# PIC32MZ2048EFM144 register map
Registers are 32-bit, access not given, reset 0x0 unless marked. A register's access mark holds for its fields unless they carry their own. Offsets are from the block's base; [hi:lo] are bit positions; {n}, {i} and the like mark numbered series; 'fields as' and 'values as' point back to an identical list.

## PMP — PMP peripheral
Base 0xBF82E000
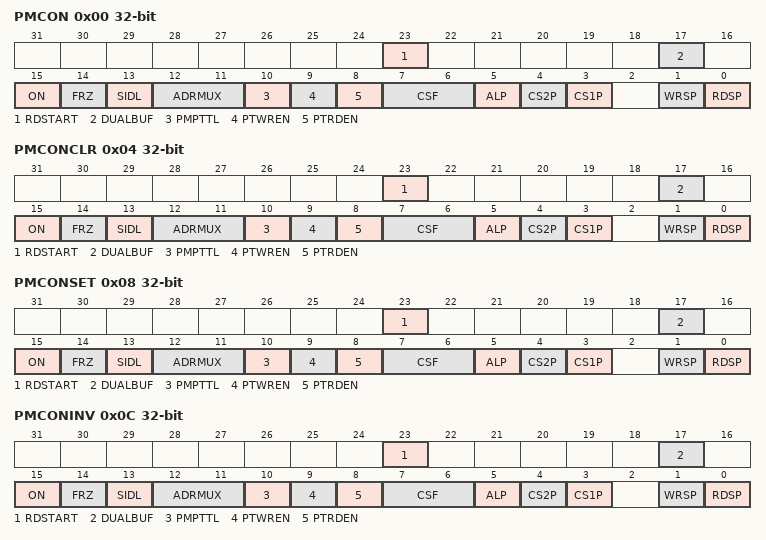
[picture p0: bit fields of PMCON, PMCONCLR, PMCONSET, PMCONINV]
0x00 PMCON
  [23] RDSTART, [17] DUALBUF, [15] ON, [14] FRZ, [13] SIDL, [12:11] ADRMUX, [10] PMPTTL, [9] PTWREN, [8] PTRDEN, [7:6] CSF, [5] ALP, [4] CS2P, [3] CS1P, [1] WRSP, [0] RDSP
0x04 PMCONCLR
  fields as PMCON
0x08 PMCONSET
  fields as PMCON
0x0C PMCONINV
  fields as PMCON
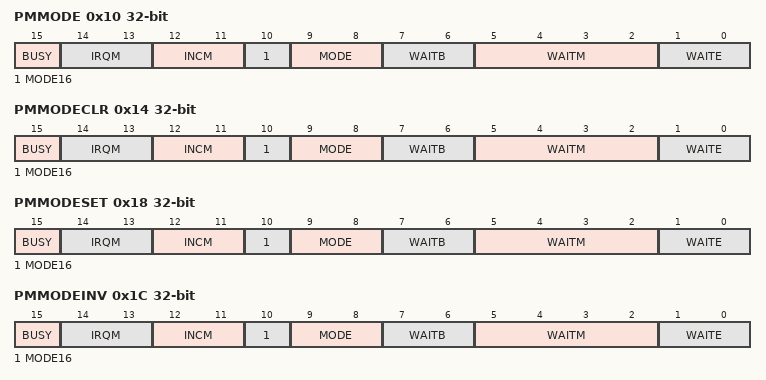
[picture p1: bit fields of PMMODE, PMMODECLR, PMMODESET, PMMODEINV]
0x10 PMMODE
  [15] BUSY, [14:13] IRQM, [12:11] INCM, [10] MODE16, [9:8] MODE, [7:6] WAITB, [5:2] WAITM, [1:0] WAITE
0x14 PMMODECLR
  fields as PMMODE
0x18 PMMODESET
  fields as PMMODE
0x1C PMMODEINV
  fields as PMMODE
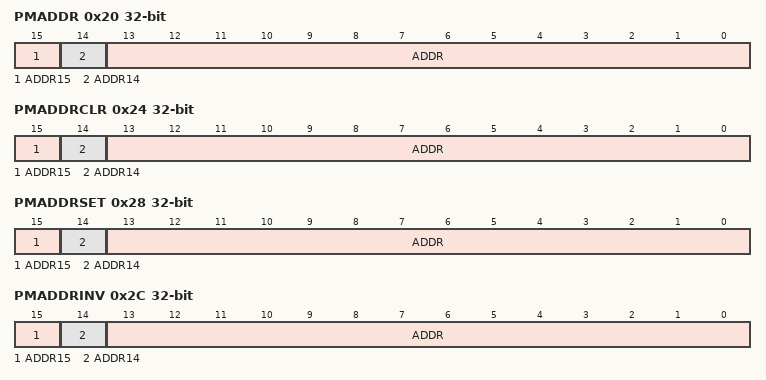
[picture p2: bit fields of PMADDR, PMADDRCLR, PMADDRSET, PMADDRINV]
0x20 PMADDR
  [15] ADDR15, [14] ADDR14, [13:0] ADDR
0x24 PMADDRCLR
  [15] ADDR15, [14] ADDR14, [13:0] ADDR
0x28 PMADDRSET
  [15] ADDR15, [14] ADDR14, [13:0] ADDR
0x2C PMADDRINV
  [15] ADDR15, [14] ADDR14, [13:0] ADDR
0x30 PMDOUT
  [31:0] DATAOUT
0x34 PMDOUTCLR
  [31:0] DATAOUT
0x38 PMDOUTSET
  [31:0] DATAOUT
0x3C PMDOUTINV
  [31:0] DATAOUT
0x40 PMDIN
  [31:0] DATAIN
0x44 PMDINCLR
  [31:0] DATAIN
0x48 PMDINSET
  [31:0] DATAIN
0x4C PMDININV
  [31:0] DATAIN
0x50 PMAEN
  [23:0] PTEN
0x54 PMAENCLR
  [23:0] PTEN
0x58 PMAENSET
  [23:0] PTEN
0x5C PMAENINV
  [23:0] PTEN
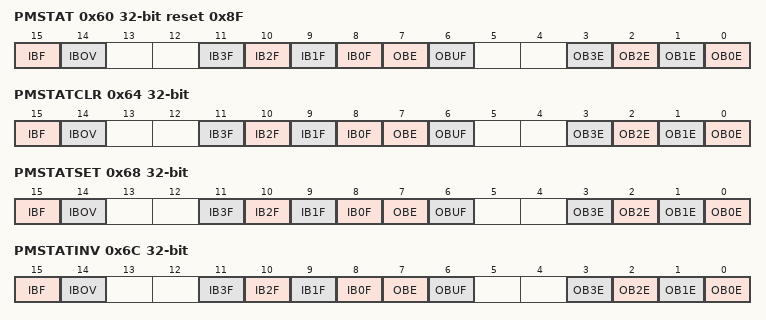
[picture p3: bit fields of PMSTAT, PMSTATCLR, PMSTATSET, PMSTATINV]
0x60 PMSTAT reset 0x8F
  [15] IBF, [14] IBOV, [n+8] IB{n}F (n=0..3), [7] OBE, [6] OBUF, [n] OB{n}E (n=0..3)
0x64 PMSTATCLR
  fields as PMSTAT
0x68 PMSTATSET
  fields as PMSTAT
0x6C PMSTATINV
  fields as PMSTAT
0x70 PMWADDR
  [23:0] WADDR
0x74 PMWADDRCLR
  [23:0] WADDR
0x78 PMWADDRSET
  [23:0] WADDR
0x7C PMWADDRINV
  [23:0] WADDR
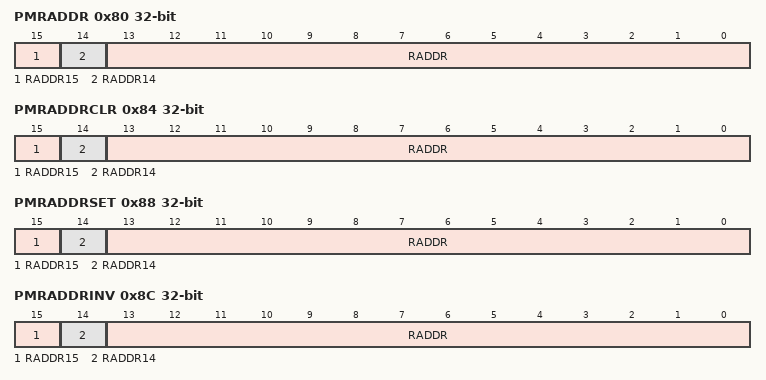
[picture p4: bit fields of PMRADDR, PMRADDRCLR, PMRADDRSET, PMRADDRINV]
0x80 PMRADDR
  [15] RADDR15, [14] RADDR14, [13:0] RADDR
0x84 PMRADDRCLR
  [15] RADDR15, [14] RADDR14, [13:0] RADDR
0x88 PMRADDRSET
  [15] RADDR15, [14] RADDR14, [13:0] RADDR
0x8C PMRADDRINV
  [15] RADDR15, [14] RADDR14, [13:0] RADDR
0x90 PMRDIN
  [31:0] RDATAIN
0x94 PMRDINCLR
  [31:0] RDATAIN
0x98 PMRDINSET
  [31:0] RDATAIN
0x9C PMRDININV
  [31:0] RDATAIN

## TMR1 — TMR1 peripheral
Base 0xBF840000
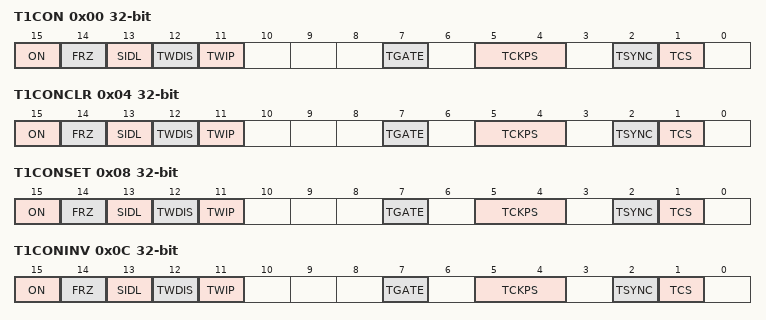
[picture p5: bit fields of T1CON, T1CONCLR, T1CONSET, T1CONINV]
0x00 T1CON
  [15] ON, [14] FRZ, [13] SIDL, [12] TWDIS, [11] TWIP, [7] TGATE, [5:4] TCKPS, [2] TSYNC, [1] TCS
0x04 T1CONCLR
  fields as T1CON
0x08 T1CONSET
  fields as T1CON
0x0C T1CONINV
  fields as T1CON
0x10 TMR1
0x14 TMR1CLR
  [31:0] TMR1
0x18 TMR1SET
  [31:0] TMR1
0x1C TMR1INV
  [31:0] TMR1
0x20 PR1 reset 0xFFFF
0x24 PR1CLR
  [31:0] PR1
0x28 PR1SET
  [31:0] PR1
0x2C PR1INV
  [31:0] PR1

## TMR2 — TMR2 peripheral
Base 0xBF840200
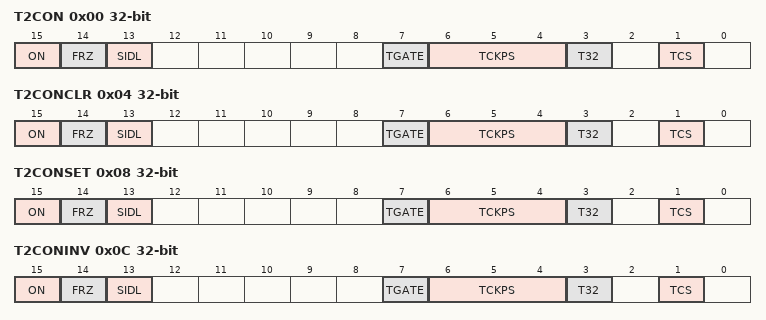
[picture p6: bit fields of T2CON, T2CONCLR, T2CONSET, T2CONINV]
0x00 T2CON
  [15] ON, [14] FRZ, [13] SIDL, [7] TGATE, [6:4] TCKPS, [3] T32, [1] TCS
0x04 T2CONCLR
  fields as T2CON
0x08 T2CONSET
  fields as T2CON
0x0C T2CONINV
  fields as T2CON
0x10 TMR2
0x14 TMR2CLR
  [31:0] TMR2
0x18 TMR2SET
  [31:0] TMR2
0x1C TMR2INV
  [31:0] TMR2
0x20 PR2 reset 0xFFFF
0x24 PR2CLR
  [31:0] PR2
0x28 PR2SET
  [31:0] PR2
0x2C PR2INV
  [31:0] PR2

## TMR3 — TMR3 peripheral
Base 0xBF840400
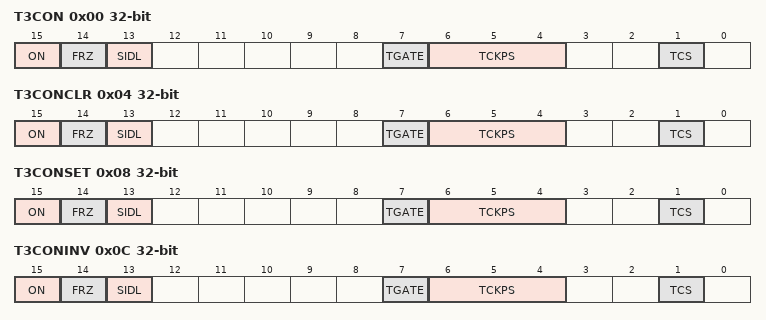
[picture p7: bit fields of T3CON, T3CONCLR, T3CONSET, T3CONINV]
0x00 T3CON
  [15] ON, [14] FRZ, [13] SIDL, [7] TGATE, [6:4] TCKPS, [1] TCS
0x04 T3CONCLR
  [15] ON, [14] FRZ, [13] SIDL, [7] TGATE, [6:4] TCKPS, [1] TCS
0x08 T3CONSET
  [15] ON, [14] FRZ, [13] SIDL, [7] TGATE, [6:4] TCKPS, [1] TCS
0x0C T3CONINV
  [15] ON, [14] FRZ, [13] SIDL, [7] TGATE, [6:4] TCKPS, [1] TCS
0x10 TMR3
0x14 TMR3CLR
  [31:0] TMR3
0x18 TMR3SET
  [31:0] TMR3
0x1C TMR3INV
  [31:0] TMR3
0x20 PR3 reset 0xFFFF
0x24 PR3CLR
  [31:0] PR3
0x28 PR3SET
  [31:0] PR3
0x2C PR3INV
  [31:0] PR3

## TMR4 — TMR4 peripheral
Base 0xBF840600
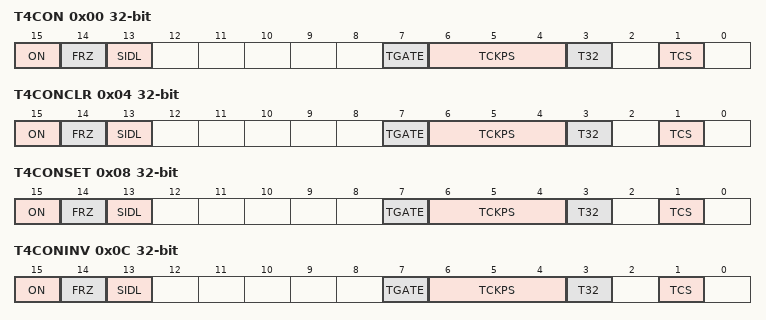
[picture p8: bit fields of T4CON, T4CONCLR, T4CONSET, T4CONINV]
0x00 T4CON
  [15] ON, [14] FRZ, [13] SIDL, [7] TGATE, [6:4] TCKPS, [3] T32, [1] TCS
0x04 T4CONCLR
  fields as T4CON
0x08 T4CONSET
  fields as T4CON
0x0C T4CONINV
  fields as T4CON
0x10 TMR4
0x14 TMR4CLR
  [31:0] TMR4
0x18 TMR4SET
  [31:0] TMR4
0x1C TMR4INV
  [31:0] TMR4
0x20 PR4 reset 0xFFFF
0x24 PR4CLR
  [31:0] PR4
0x28 PR4SET
  [31:0] PR4
0x2C PR4INV
  [31:0] PR4

## TMR5 — TMR5 peripheral
Base 0xBF840800
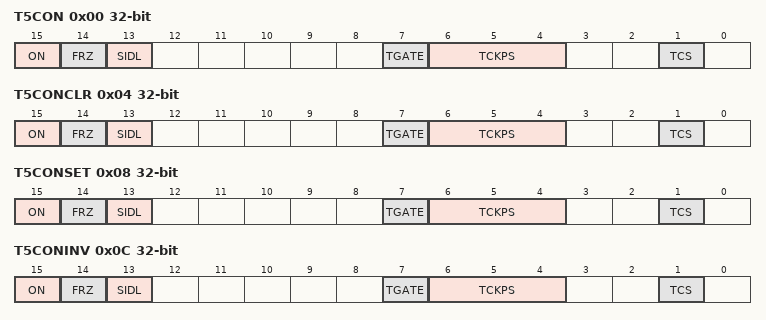
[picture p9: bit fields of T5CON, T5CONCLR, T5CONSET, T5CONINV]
0x00 T5CON
  [15] ON, [14] FRZ, [13] SIDL, [7] TGATE, [6:4] TCKPS, [1] TCS
0x04 T5CONCLR
  [15] ON, [14] FRZ, [13] SIDL, [7] TGATE, [6:4] TCKPS, [1] TCS
0x08 T5CONSET
  [15] ON, [14] FRZ, [13] SIDL, [7] TGATE, [6:4] TCKPS, [1] TCS
0x0C T5CONINV
  [15] ON, [14] FRZ, [13] SIDL, [7] TGATE, [6:4] TCKPS, [1] TCS
0x10 TMR5
0x14 TMR5CLR
  [31:0] TMR5
0x18 TMR5SET
  [31:0] TMR5
0x1C TMR5INV
  [31:0] TMR5
0x20 PR5 reset 0xFFFF
0x24 PR5CLR
  [31:0] PR5
0x28 PR5SET
  [31:0] PR5
0x2C PR5INV
  [31:0] PR5
